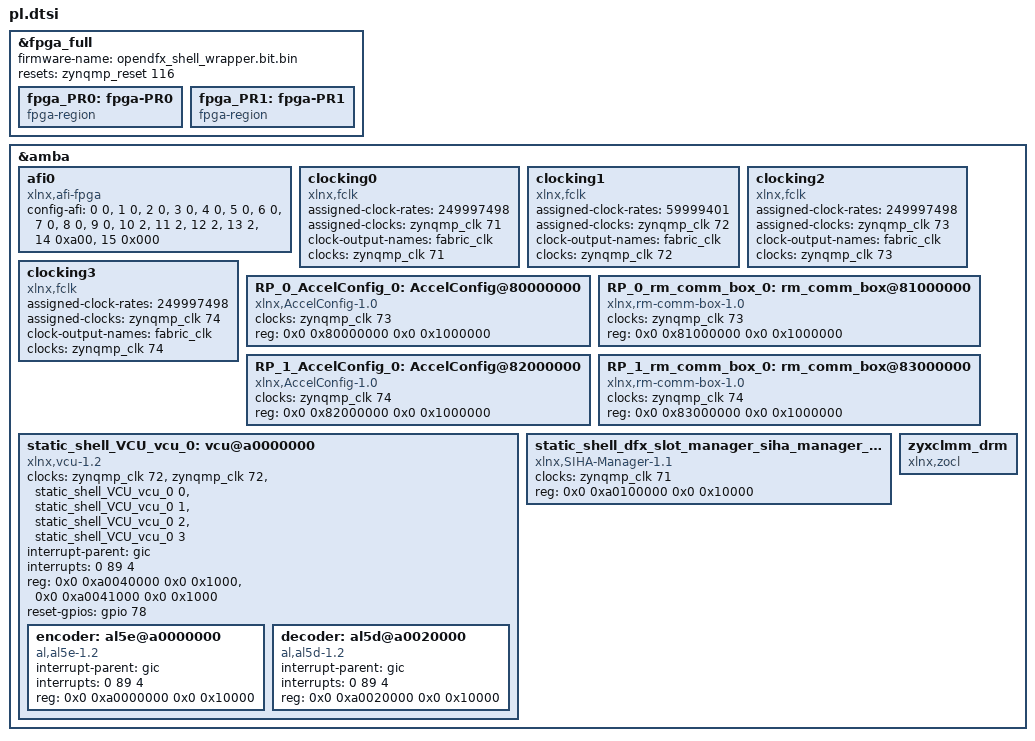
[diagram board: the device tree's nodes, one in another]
/*
 * CAUTION: This file is automatically generated by Xilinx.
 * Version: XSCT 2022.1
 * Today is: Tue Apr  5 09:01:00 2022
 */


/dts-v1/;
/plugin/;
/ {
	fragment@0 {
		target = <&fpga_full>;
		overlay0: __overlay__ {
			#address-cells = <2>;
			#size-cells = <2>;
			firmware-name = "opendfx_shell_wrapper.bit.bin";
			resets = <&zynqmp_reset 116>;
			fpga_PR0: fpga-PR0 {
				#address-cells = <2>;
				#size-cells = <2>;
				compatible = "fpga-region";
				ranges ;
			};
			fpga_PR1: fpga-PR1 {
				#address-cells = <2>;
				#size-cells = <2>;
				compatible = "fpga-region";
				ranges ;
			};
		};
	};
	fragment@1 {
		target = <&amba>;
		overlay1: __overlay__ {
			afi0: afi0 {
				compatible = "xlnx,afi-fpga";
				config-afi = < 0 0>, <1 0>, <2 0>, <3 0>, <4 0>, <5 0>, <6 0>, <7 0>, <8 0>, <9 0>, <10 2>, <11 2>, <12 2>, <13 2>, <14 0xa00>, <15 0x000>;
			};
			clocking0: clocking0 {
				#clock-cells = <0>;
				assigned-clock-rates = <249997498>;
				assigned-clocks = <&zynqmp_clk 71>;
				clock-output-names = "fabric_clk";
				clocks = <&zynqmp_clk 71>;
				compatible = "xlnx,fclk";
			};
			clocking1: clocking1 {
				#clock-cells = <0>;
				assigned-clock-rates = <59999401>;
				assigned-clocks = <&zynqmp_clk 72>;
				clock-output-names = "fabric_clk";
				clocks = <&zynqmp_clk 72>;
				compatible = "xlnx,fclk";
			};
			clocking2: clocking2 {
				#clock-cells = <0>;
				assigned-clock-rates = <249997498>;
				assigned-clocks = <&zynqmp_clk 73>;
				clock-output-names = "fabric_clk";
				clocks = <&zynqmp_clk 73>;
				compatible = "xlnx,fclk";
			};
			clocking3: clocking3 {
				#clock-cells = <0>;
				assigned-clock-rates = <249997498>;
				assigned-clocks = <&zynqmp_clk 74>;
				clock-output-names = "fabric_clk";
				clocks = <&zynqmp_clk 74>;
				compatible = "xlnx,fclk";
			};
		};
	};
	fragment@2 {
		target = <&amba>;
		overlay2: __overlay__ {
			#address-cells = <2>;
			#size-cells = <2>;
			RP_0_AccelConfig_0: AccelConfig@80000000 {
				/* This is a place holder node for a custom IP, user may need to update the entries */
				clock-names = "clk";
				clocks = <&zynqmp_clk 73>;
				compatible = "xlnx,AccelConfig-1.0", "generic-uio";
				reg = <0x0 0x80000000 0x0 0x1000000>;
			};
			RP_0_rm_comm_box_0: rm_comm_box@81000000 {
				/* This is a place holder node for a custom IP, user may need to update the entries */
				clock-names = "clk";
				clocks = <&zynqmp_clk 73>;
				compatible = "xlnx,rm-comm-box-1.0", "generic-uio";
				reg = <0x0 0x81000000 0x0 0x1000000>;
			};
			RP_1_AccelConfig_0: AccelConfig@82000000 {
				/* This is a place holder node for a custom IP, user may need to update the entries */
				clock-names = "clk";
				clocks = <&zynqmp_clk 74>;
				compatible = "xlnx,AccelConfig-1.0", "generic-uio";
				reg = <0x0 0x82000000 0x0 0x1000000>;
			};
			RP_1_rm_comm_box_0: rm_comm_box@83000000 {
				/* This is a place holder node for a custom IP, user may need to update the entries */
				clock-names = "clk";
				clocks = <&zynqmp_clk 74>;
				compatible = "xlnx,rm-comm-box-1.0", "generic-uio";
				reg = <0x0 0x83000000 0x0 0x1000000>;
			};
			static_shell_VCU_vcu_0: vcu@a0000000 {
				#address-cells = <2>;
				#clock-cells = <1>;
				#size-cells = <2>;
				clock-names = "pll_ref", "aclk", "vcu_core_enc", "vcu_mcu_enc", "vcu_core_dec", "vcu_mcu_dec";
				clocks = <&zynqmp_clk 72>, <&zynqmp_clk 72>, <&static_shell_VCU_vcu_0 0>, <&static_shell_VCU_vcu_0 1>, <&static_shell_VCU_vcu_0 2>, <&static_shell_VCU_vcu_0 3>;
				compatible = "xlnx,vcu-1.2", "xlnx,vcu";
				interrupt-names = "vcu_host_interrupt";
				interrupt-parent = <&gic>;
				interrupts = <0 89 4>;
				ranges ;
				reg = <0x0 0xa0040000 0x0 0x1000>, <0x0 0xa0041000 0x0 0x1000>;
				reg-names = "vcu_slcr", "logicore";
				reset-gpios = <&gpio 78 0>;
				encoder: al5e@a0000000 {
					compatible = "al,al5e-1.2", "al,al5e";
					interrupt-parent = <&gic>;
					interrupts = <0 89 4>;
					reg = <0x0 0xa0000000 0x0 0x10000>;
				};
				decoder: al5d@a0020000 {
					compatible = "al,al5d-1.2", "al,al5d";
					interrupt-parent = <&gic>;
					interrupts = <0 89 4>;
					reg = <0x0 0xa0020000 0x0 0x10000>;
				};
			};
			static_shell_dfx_slot_manager_siha_manager_0: SIHA_Manager@a0100000 {
				/* This is a place holder node for a custom IP, user may need to update the entries */
				clock-names = "clk";
				clocks = <&zynqmp_clk 71>;
				compatible = "xlnx,SIHA-Manager-1.1","generic-uio";
				reg = <0x0 0xa0100000 0x0 0x10000>;
			};
			zyxclmm_drm {
				compatible = "xlnx,zocl";
				status = "okay";
			};
		};
	};
};
